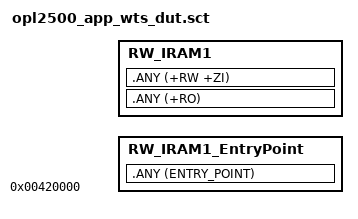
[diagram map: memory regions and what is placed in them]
#! armcc -E
        
;FIXME, Checking patch start address
#define APS_PATCH_START         0x00420000
#define APS_DM_REGION_START     0x00444000
#define APS_PATCH_LEN           APS_DM_REGION_START-APS_PATCH_START

LR_IROM1 APS_PATCH_START APS_PATCH_LEN
{
    RW_IRAM1_EntryPoint +0
    {
        .ANY (ENTRY_POINT)
    }
    RW_IRAM1 +0 
    {
       .ANY (+RO)
       .ANY (+RW +ZI)
    }
}
ScatterAssert(ImageLength(LR_IROM1) <= APS_PATCH_LEN)
